AUTOSAR XML (schema 4-2-2)
package /STELLANTIS/EPT/ASWCs
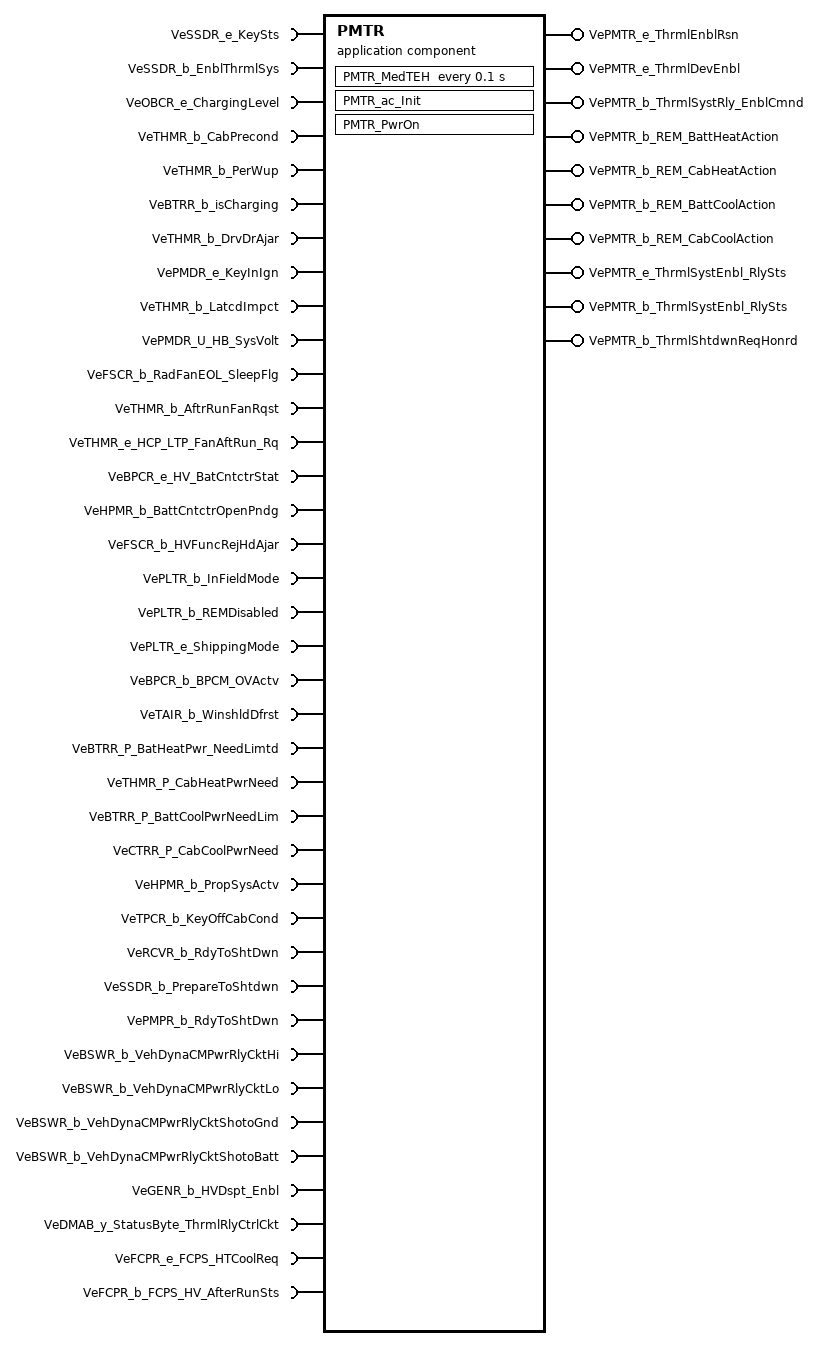
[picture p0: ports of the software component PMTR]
  application sw component type PMTR
    38 x require port:
      VeSSDR_e_KeySts: nonqueued-receiver-com-spec{data-element=Value, init-value=CeSSDR_e_KeyOff}, required-interface=VeSSDR_e_KeySts
      VeSSDR_b_EnblThrmlSys: nonqueued-receiver-com-spec{data-element=Value, init-value=0}, required-interface=VeSSDR_b_EnblThrmlSys
      VeOBCR_e_ChargingLevel: nonqueued-receiver-com-spec{data-element=Value, init-value=CeOBCR_e_ChargingLvlDefault}, required-interface=VeOBCR_e_ChargingLevel
      VeTHMR_b_CabPrecond: nonqueued-receiver-com-spec{data-element=Value, init-value=0}, required-interface=VeTHMR_b_CabPrecond
      VeTHMR_b_PerWup: nonqueued-receiver-com-spec{data-element=Value, init-value=0}, required-interface=VeTHMR_b_PerWup
      VeBTRR_b_isCharging: nonqueued-receiver-com-spec{data-element=Value, init-value=0}, required-interface=VeBTRR_b_isCharging
      VeTHMR_b_DrvDrAjar: nonqueued-receiver-com-spec{data-element=Value, init-value=0}, required-interface=VeTHMR_b_DrvDrAjar
      VePMDR_e_KeyInIgn: nonqueued-receiver-com-spec{data-element=Value, init-value=CePMDR_e_KeyInIgn_DEFAULT}, required-interface=VePMDR_e_KeyInIgn
      VeTHMR_b_LatcdImpct: nonqueued-receiver-com-spec{data-element=Value, init-value=0}, required-interface=VeTHMR_b_LatcdImpct
      VePMDR_U_HB_SysVolt: nonqueued-receiver-com-spec{data-element=Value, init-value=0}, required-interface=VePMDR_U_HB_SysVolt
      VeFSCR_b_RadFanEOL_SleepFlg: nonqueued-receiver-com-spec{data-element=Value, init-value=0}, required-interface=VeFSCR_b_RadFanEOL_SleepFlg
      VeTHMR_b_AftrRunFanRqst: nonqueued-receiver-com-spec{data-element=Value, init-value=0}, required-interface=VeTHMR_b_AftrRunFanRqst
      VeTHMR_e_HCP_LTP_FanAftRun_Rq: nonqueued-receiver-com-spec{data-element=Value, init-value=CeTMIR_e_No_AftRunRequest}, required-interface=VeTHMR_e_HCP_LTP_FanAftRun_Rq
      VeBPCR_e_HV_BatCntctrStat: nonqueued-receiver-com-spec{data-element=Value, init-value=CeHVTR_e_Open}, required-interface=VeBPCR_e_HV_BatCntctrStat
      VeHPMR_b_BattCntctrOpenPndg: nonqueued-receiver-com-spec{data-element=Value, init-value=0}, required-interface=VeHPMR_b_BattCntctrOpenPndg
      VeFSCR_b_HVFuncRejHdAjar: nonqueued-receiver-com-spec{data-element=Value, init-value=0}, required-interface=VeFSCR_b_HVFuncRejHdAjar
      VePLTR_b_InFieldMode: nonqueued-receiver-com-spec{data-element=Value, init-value=0}, required-interface=VePLTR_b_InFieldMode
      VePLTR_b_REMDisabled: nonqueued-receiver-com-spec{data-element=Value, init-value=0}, required-interface=VePLTR_b_REMDisabled
      VePLTR_e_ShippingMode: nonqueued-receiver-com-spec{data-element=Value, init-value=CePLTR_e_ShipingMode_CUST_MD}, required-interface=VePLTR_e_ShippingMode
      VeBPCR_b_BPCM_OVActv: nonqueued-receiver-com-spec{data-element=Value, init-value=0}, required-interface=VeBPCR_b_BPCM_OVActv
      VeTAIR_b_WinshldDfrst: nonqueued-receiver-com-spec{data-element=Value, init-value=0}, required-interface=VeTAIR_b_WinshldDfrst
      VeBTRR_P_BatHeatPwr_NeedLimtd: nonqueued-receiver-com-spec{data-element=Value, init-value=0}, required-interface=VeBTRR_P_BatHeatPwr_NeedLimtd
      VeTHMR_P_CabHeatPwrNeed: nonqueued-receiver-com-spec{data-element=Value, init-value=0}, required-interface=VeTHMR_P_CabHeatPwrNeed
      VeBTRR_P_BattCoolPwrNeedLim: nonqueued-receiver-com-spec{data-element=Value, init-value=0}, required-interface=VeBTRR_P_BattCoolPwrNeedLim
      VeCTRR_P_CabCoolPwrNeed: nonqueued-receiver-com-spec{data-element=Value, init-value=0}, required-interface=VeCTRR_P_CabCoolPwrNeed
      VeHPMR_b_PropSysActv: nonqueued-receiver-com-spec{data-element=Value, init-value=0}, required-interface=VeHPMR_b_PropSysActv
      VeTPCR_b_KeyOffCabCond: nonqueued-receiver-com-spec{data-element=Value, init-value=0}, required-interface=VeTPCR_b_KeyOffCabCond
      VeRCVR_b_RdyToShtDwn: nonqueued-receiver-com-spec{data-element=Value, init-value=0}, required-interface=VeRCVR_b_RdyToShtDwn
      VeSSDR_b_PrepareToShtdwn: nonqueued-receiver-com-spec{data-element=Value, init-value=0}, required-interface=VeSSDR_b_PrepareToShtdwn
      VePMPR_b_RdyToShtDwn: nonqueued-receiver-com-spec{data-element=Value, init-value=0}, required-interface=VePMPR_b_RdyToShtDwn
      VeBSWR_b_VehDynaCMPwrRlyCktHi: nonqueued-receiver-com-spec{data-element=Value, init-value=0}, required-interface=VeBSWR_b_VehDynaCMPwrRlyCktHi
      VeBSWR_b_VehDynaCMPwrRlyCktLo: nonqueued-receiver-com-spec{data-element=Value, init-value=0}, required-interface=VeBSWR_b_VehDynaCMPwrRlyCktLo
      VeBSWR_b_VehDynaCMPwrRlyCktShotoGnd: nonqueued-receiver-com-spec{data-element=Value, init-value=0}, required-interface=VeBSWR_b_VehDynaCMPwrRlyCktShotoGnd
      VeBSWR_b_VehDynaCMPwrRlyCktShotoBatt: nonqueued-receiver-com-spec{data-element=Value, init-value=0}, required-interface=VeBSWR_b_VehDynaCMPwrRlyCktShotoBatt
      VeGENR_b_HVDspt_Enbl: nonqueued-receiver-com-spec{data-element=Value, init-value=0}, required-interface=VeGENR_b_HVDspt_Enbl
      VeDMAB_y_StatusByte_ThrmlRlyCtrlCkt: nonqueued-receiver-com-spec{data-element=Value, init-value=0}, required-interface=VeDMAB_y_StatusByte_ThrmlRlyCtrlCkt
      VeFCPR_e_FCPS_HTCoolReq: nonqueued-receiver-com-spec{data-element=Value, init-value=CeFCPR_e_No_Request}, required-interface=VeFCPR_e_FCPS_HTCoolReq
      VeFCPR_b_FCPS_HV_AfterRunSts: nonqueued-receiver-com-spec{data-element=Value, init-value=0}, required-interface=VeFCPR_b_FCPS_HV_AfterRunSts
    10 x provide port:
      VePMTR_e_ThrmlEnblRsn: nonqueued-sender-com-spec{data-element=Value, init-value=CePMTR_e_EnblKey_Acc_or_DrvDoorAjr}, provided-interface=VePMTR_e_ThrmlEnblRsn
      VePMTR_e_ThrmlDevEnbl: nonqueued-sender-com-spec{data-element=Value, init-value=CePMTR_e_DISBL_All_Thrml}, provided-interface=VePMTR_e_ThrmlDevEnbl
      VePMTR_b_ThrmlSystRly_EnblCmnd: nonqueued-sender-com-spec{data-element=Value, init-value=0}, provided-interface=VePMTR_b_ThrmlSystRly_EnblCmnd
      VePMTR_b_REM_BattHeatAction: nonqueued-sender-com-spec{data-element=Value, init-value=0}, provided-interface=VePMTR_b_REM_BattHeatAction
      VePMTR_b_REM_CabHeatAction: nonqueued-sender-com-spec{data-element=Value, init-value=0}, provided-interface=VePMTR_b_REM_CabHeatAction
      VePMTR_b_REM_BattCoolAction: nonqueued-sender-com-spec{data-element=Value, init-value=0}, provided-interface=VePMTR_b_REM_BattCoolAction
      VePMTR_b_REM_CabCoolAction: nonqueued-sender-com-spec{data-element=Value, init-value=0}, provided-interface=VePMTR_b_REM_CabCoolAction
      VePMTR_e_ThrmlSystEnbl_RlySts: nonqueued-sender-com-spec{data-element=Value, init-value=CePMTR_e_ThermalRelay_SNA}, provided-interface=VePMTR_e_ThrmlSystEnbl_RlySts
      VePMTR_b_ThrmlSystEnbl_RlySts: nonqueued-sender-com-spec{data-element=Value, init-value=0}, provided-interface=VePMTR_b_ThrmlSystEnbl_RlySts
      VePMTR_b_ThrmlShtdwnReqHonrd: nonqueued-sender-com-spec{data-element=Value, init-value=0}, provided-interface=VePMTR_b_ThrmlShtdwnReqHonrd
    behavior IB_PMTR: data-type-mapping=msADTtoIDTMapping, handle-termination-and-restart=NO-SUPPORT, included-data-type-set=data-type=TePMTR_e_VehicleMode
      timing event Event_MedTEH: start-on-event=PMTR_MedTEH, period=0.1
      init event Event_PMTR_ac_Init: start-on-event=PMTR_ac_Init
      init event Event_PwrOn: start-on-event=PMTR_PwrOn
      runnable PMTR_ac_Init
        data-send-points:
          access OUT_VePMTR_e_ThrmlEnblRsn_Value: accessed-variable=VePMTR_e_ThrmlEnblRsn.Value
          access OUT_VePMTR_e_ThrmlDevEnbl_Value: accessed-variable=VePMTR_e_ThrmlDevEnbl.Value
          access OUT_VePMTR_e_ThrmlSystEnbl_RlySts_Value: accessed-variable=VePMTR_e_ThrmlSystEnbl_RlySts.Value
      runnable PMTR_MedTEH
        data-receive-point-by-arguments:
          38 x access:
            IN_VeBPCR_b_BPCM_OVActv_Value: accessed-variable=VeBPCR_b_BPCM_OVActv.Value
            IN_VeBPCR_e_HV_BatCntctrStat_Value: accessed-variable=VeBPCR_e_HV_BatCntctrStat.Value
            IN_VeBSWR_b_VehDynaCMPwrRlyCktHi_Value: accessed-variable=VeBSWR_b_VehDynaCMPwrRlyCktHi.Value
            IN_VeBSWR_b_VehDynaCMPwrRlyCktLo_Value: accessed-variable=VeBSWR_b_VehDynaCMPwrRlyCktLo.Value
            IN_VeBSWR_b_VehDynaCMPwrRlyCktShotoBatt_Value: accessed-variable=VeBSWR_b_VehDynaCMPwrRlyCktShotoBatt.Value
            IN_VeBSWR_b_VehDynaCMPwrRlyCktShotoGnd_Value: accessed-variable=VeBSWR_b_VehDynaCMPwrRlyCktShotoGnd.Value
            IN_VeBTRR_P_BatHeatPwr_NeedLimtd_Value: accessed-variable=VeBTRR_P_BatHeatPwr_NeedLimtd.Value
            IN_VeBTRR_P_BattCoolPwrNeedLim_Value: accessed-variable=VeBTRR_P_BattCoolPwrNeedLim.Value
            IN_VeBTRR_b_isCharging_Value: accessed-variable=VeBTRR_b_isCharging.Value
            IN_VeCTRR_P_CabCoolPwrNeed_Value: accessed-variable=VeCTRR_P_CabCoolPwrNeed.Value
            IN_VeDMAB_y_StatusByte_ThrmlRlyCtrlCkt_Value: accessed-variable=VeDMAB_y_StatusByte_ThrmlRlyCtrlCkt.Value
            IN_VeFCPR_b_FCPS_HV_AfterRunSts_Value: accessed-variable=VeFCPR_b_FCPS_HV_AfterRunSts.Value
            IN_VeFCPR_e_FCPS_HTCoolReq_Value: accessed-variable=VeFCPR_e_FCPS_HTCoolReq.Value
            IN_VeFSCR_b_HVFuncRejHdAjar_Value: accessed-variable=VeFSCR_b_HVFuncRejHdAjar.Value
            IN_VeFSCR_b_RadFanEOL_SleepFlg_Value: accessed-variable=VeFSCR_b_RadFanEOL_SleepFlg.Value
            IN_VeGENR_b_HVDspt_Enbl_Value: accessed-variable=VeGENR_b_HVDspt_Enbl.Value
            IN_VeHPMR_b_BattCntctrOpenPndg_Value: accessed-variable=VeHPMR_b_BattCntctrOpenPndg.Value
            IN_VeHPMR_b_PropSysActv_Value: accessed-variable=VeHPMR_b_PropSysActv.Value
            IN_VeOBCR_e_ChargingLevel_Value: accessed-variable=VeOBCR_e_ChargingLevel.Value
            IN_VePLTR_b_InFieldMode_Value: accessed-variable=VePLTR_b_InFieldMode.Value
            IN_VePLTR_b_REMDisabled_Value: accessed-variable=VePLTR_b_REMDisabled.Value
            IN_VePLTR_e_ShippingMode_Value: accessed-variable=VePLTR_e_ShippingMode.Value
            IN_VePMDR_U_HB_SysVolt_Value: accessed-variable=VePMDR_U_HB_SysVolt.Value
            IN_VePMDR_e_KeyInIgn_Value: accessed-variable=VePMDR_e_KeyInIgn.Value
            IN_VePMPR_b_RdyToShtDwn_Value: accessed-variable=VePMPR_b_RdyToShtDwn.Value
            IN_VeRCVR_b_RdyToShtDwn_Value: accessed-variable=VeRCVR_b_RdyToShtDwn.Value
            IN_VeSSDR_b_EnblThrmlSys_Value: accessed-variable=VeSSDR_b_EnblThrmlSys.Value
            IN_VeSSDR_b_PrepareToShtdwn_Value: accessed-variable=VeSSDR_b_PrepareToShtdwn.Value
            IN_VeSSDR_e_KeySts_Value: accessed-variable=VeSSDR_e_KeySts.Value
            IN_VeTAIR_b_WinshldDfrst_Value: accessed-variable=VeTAIR_b_WinshldDfrst.Value
            IN_VeTHMR_P_CabHeatPwrNeed_Value: accessed-variable=VeTHMR_P_CabHeatPwrNeed.Value
            IN_VeTHMR_b_AftrRunFanRqst_Value: accessed-variable=VeTHMR_b_AftrRunFanRqst.Value
            IN_VeTHMR_b_CabPrecond_Value: accessed-variable=VeTHMR_b_CabPrecond.Value
            IN_VeTHMR_b_DrvDrAjar_Value: accessed-variable=VeTHMR_b_DrvDrAjar.Value
            IN_VeTHMR_b_LatcdImpct_Value: accessed-variable=VeTHMR_b_LatcdImpct.Value
            IN_VeTHMR_b_PerWup_Value: accessed-variable=VeTHMR_b_PerWup.Value
            IN_VeTHMR_e_HCP_LTP_FanAftRun_Rq_Value: accessed-variable=VeTHMR_e_HCP_LTP_FanAftRun_Rq.Value
            IN_VeTPCR_b_KeyOffCabCond_Value: accessed-variable=VeTPCR_b_KeyOffCabCond.Value
        data-send-points:
          10 x access:
            OUT_VePMTR_e_ThrmlEnblRsn_Value: accessed-variable=VePMTR_e_ThrmlEnblRsn.Value
            OUT_VePMTR_e_ThrmlDevEnbl_Value: accessed-variable=VePMTR_e_ThrmlDevEnbl.Value
            OUT_VePMTR_b_ThrmlShtdwnReqHonrd_Value: accessed-variable=VePMTR_b_ThrmlShtdwnReqHonrd.Value
            OUT_VePMTR_b_ThrmlSystRly_EnblCmnd_Value: accessed-variable=VePMTR_b_ThrmlSystRly_EnblCmnd.Value
            OUT_VePMTR_e_ThrmlSystEnbl_RlySts_Value: accessed-variable=VePMTR_e_ThrmlSystEnbl_RlySts.Value
            OUT_VePMTR_b_ThrmlSystEnbl_RlySts_Value: accessed-variable=VePMTR_b_ThrmlSystEnbl_RlySts.Value
            OUT_VePMTR_b_REM_BattHeatAction_Value: accessed-variable=VePMTR_b_REM_BattHeatAction.Value
            OUT_VePMTR_b_REM_CabHeatAction_Value: accessed-variable=VePMTR_b_REM_CabHeatAction.Value
            OUT_VePMTR_b_REM_BattCoolAction_Value: accessed-variable=VePMTR_b_REM_BattCoolAction.Value
            OUT_VePMTR_b_REM_CabCoolAction_Value: accessed-variable=VePMTR_b_REM_CabCoolAction.Value
      runnable PMTR_PwrOn
        data-send-points:
          10 x access:
            OUT_VePMTR_e_ThrmlEnblRsn_Value: accessed-variable=VePMTR_e_ThrmlEnblRsn.Value
            OUT_VePMTR_e_ThrmlDevEnbl_Value: accessed-variable=VePMTR_e_ThrmlDevEnbl.Value
            OUT_VePMTR_b_ThrmlSystRly_EnblCmnd_Value: accessed-variable=VePMTR_b_ThrmlSystRly_EnblCmnd.Value
            OUT_VePMTR_b_REM_BattHeatAction_Value: accessed-variable=VePMTR_b_REM_BattHeatAction.Value
            OUT_VePMTR_b_REM_CabHeatAction_Value: accessed-variable=VePMTR_b_REM_CabHeatAction.Value
            OUT_VePMTR_b_REM_BattCoolAction_Value: accessed-variable=VePMTR_b_REM_BattCoolAction.Value
            OUT_VePMTR_b_REM_CabCoolAction_Value: accessed-variable=VePMTR_b_REM_CabCoolAction.Value
            OUT_VePMTR_e_ThrmlSystEnbl_RlySts_Value: accessed-variable=VePMTR_e_ThrmlSystEnbl_RlySts.Value
            OUT_VePMTR_b_ThrmlSystEnbl_RlySts_Value: accessed-variable=VePMTR_b_ThrmlSystEnbl_RlySts.Value
            OUT_VePMTR_b_ThrmlShtdwnReqHonrd_Value: accessed-variable=VePMTR_b_ThrmlShtdwnReqHonrd.Value
      variation point proxy Variant_PMTR_1: category=CONDITION, condition-access=0
      variation point proxy Variant_PMTR_3: category=CONDITION, condition-access=1
